# F28x7x_i2c_regs register map
Vendor: Texas Instruments
Peripheral module from a debugger description file (folder C2000).
Address unit: 16 bits
Registers are 16-bit, read-write, no defined reset value unless marked. A register's access mark holds for its fields unless they carry their own. Offsets are as the file gives them; lines under a group give offsets from that group; [hi:lo] are bit positions; {n}, {i} and the like mark numbered series; 'fields as' and 'values as' point back to an identical list; <NAME> marks a mode.

## I2C_REGS
0x00 I2COAR — I2C Own address
  [9:0] OAR
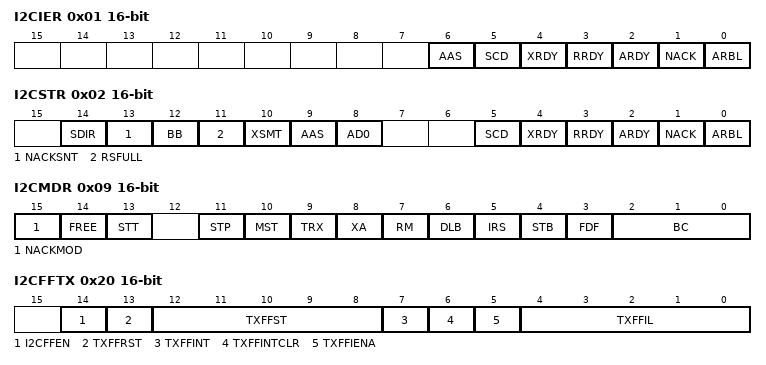
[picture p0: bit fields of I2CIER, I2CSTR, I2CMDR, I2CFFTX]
0x01 I2CIER — I2C Interrupt Enable
  [all] fields
    0=Interrupt request disabled; 1=Interrupt request enabled
  [6] AAS — Addressed as slave interrupt enable
  [5] SCD — Stop condition detected interrupt enable
  [4] XRDY — Transmit-data-ready interrupt enable
  [3] RRDY — Receive-data-ready interrupt enable
  [2] ARDY — Register-access-ready interrupt enable
  [1] NACK — No-acknowledgment interrupt enable
  [0] ARBL — Arbitration-lost interrupt enable
0x02 I2CSTR — I2C Status
  [14] SDIR — Slave direction bit
    0=I2C is not addressed as a slave transmitter; 1=I2C is addressed as a slave transmitter
  [13] NACKSNT — NACK sent bit.
    0=NACK not sent; 1=NACK sent: A no-acknowledge bit was sent during the acknowledge
  [12] BB — Bus busy bit.
    0=Bus free; 1=Bus busy: The I2C module has received or transmitted a START bi
  [11] RSFULL — Receive shift register full bit.
    0=No overrun detected; 1=Overrun detected
  [10] XSMT — Transmit shift register empty bit.
    0=Underflow detected (empty); 1=No underflow detected (not empty)
  [9] AAS — Addressed-as-slave bit
    0=In the 7-bit addressing mode, the AAS bit is cleared when recei; 1=The I2C module has recognized its own slave address or an addre
  [8] AD0 — Address 0 bits
    0=AD0 has been cleared by a START or STOP condition; 1=An address of all zeros (general call) is detected
  [5] SCD — Stop condition detected bit.
    0=STOP condition not detected since SCD was last cleared; 1=A STOP condition has been detected on the I2C bus
  [4] XRDY — Transmit-data-ready interrupt flag bit.
    0=I2CDXR not ready; 1=I2CDXR ready: Data has been copied from I2CDXR to I2CXSR
  [3] RRDY — Receive-data-ready interrupt flag bit.
    0=I2CDRR not ready; 1=I2CDRR ready: Data has been copied from I2CRSR to I2CDRR
  [2] ARDY — Register-access-ready interrupt flag bit
    0=The registers are not ready to be accessed; 1=The registers are ready to be accessed
  [1] NACK — No-acknowledgment interrupt flag bit.
    0=ACK received/NACK not received; 1=NACK bit received
  [0] ARBL — Arbitration-lost interrupt flag bit
    0=Arbitration not lost; 1=Arbitration lost
0x03 I2CCLKL — I2C Clock low-time divider
  [15:0] I2CCLKL — Clock low-time divide-down value.
0x04 I2CCLKH — I2C Clock high-time divider
  [15:0] I2CCLKH — Clock high-time divide-down value.
0x05 I2CCNT — I2C Data count
  [15:0] I2CCNT — Data count value.
0x06 I2CDRR — I2C Data receive
  [7:0] DATA — Receive data
0x07 I2CSAR — I2C Slave address
  [9:0] SAR — Slave Address
0x08 I2CDXR — I2C Data Transmit
  [7:0] DATA — Transmit data
0x09 I2CMDR — I2C Mode
  [15] NACKMOD — NACK mode bit
    0=In the slave-receiver mode: The I2C module sends an acknowledge; 1=In either slave-receiver or master-receiver mode: The I2C modul
  [14] FREE — Debug Action
    0=When I2C module is master:[[br]]If SCL is low when the breakpoi; 1=The I2C module runs free; that is, it continues to operate when
  [13] STT — START condition bit
    0=In the master mode, STT is automatically cleared after the STAR; 1=In the master mode, setting STT to 1 causes the I2C module to g
  [11] STP — STOP Condition
    0=STP is automatically cleared after the STOP condition has been; 1=STP has been set by the device to generate a STOP condition whe
  [10] MST — Master Mode
    0=Slave mode; 1=Master mode
  [9] TRX — Transmitter Mode
    0=Receiver mode; 1=Transmitter mode
  [8] XA — Expanded Address Mode
    0=7-bit addressing mode (normal address mode); 1=10-bit addressing mode (expanded address mode)
  [7] RM — Repeat Mode
    0=Nonrepeat mode; 1=Repeat mode
  [6] DLB — Digital Loopback Mode
    0=Digital loopback mode is disabled; 1=Digital loopback mode is enabled
  [5] IRS — I2C Module Reset
    0=The I2C module is in reset/disabled; 1=The I2C module is enabled
  [4] STB — START Byte Mode
    0=The I2C module is not in the START byte mode; 1=The I2C module is in the START byte mode
  [3] FDF — Free Data Format
    0=Free data format mode is disabled; 1=Free data format mode is enabled
  [2:0] BC — Bit count bits.
    0=8 bits per data byte; 1=1 bit per data byte; {v}=__{v} ({v} bits per data byte) (v=2..7)
0x0A I2CISRC — I2C Interrupt Source
  [2:0] INTCODE — Interrupt code bits.
    0=None; 1=Arbitration lost; 2=__2 (No-acknowledgment condition detected); 3=__3 (Registers ready to be accessed); 4=__4 (Receive data ready); 5=__5 (Transmit data ready); 6=__6 (Stop condition detected); 7=__7 (Addressed as slave)
0x0B I2CEMDR — I2C Extended Mode
  [0] BC — Backwards compatibility mode
    0=See Figure 9-17 for details; 1=See Figure 9-17 for details
0x0C I2CPSC — I2C Prescaler
  [7:0] IPSC — I2C Prescaler Divide Down
0x20 I2CFFTX — I2C FIFO Transmit
  [14] I2CFFEN — Transmit FIFO Enable
    0=Disable the I2C FIFO mode; 1=Enable the I2C FIFO mode
  [13] TXFFRST — Transmit FIFO Reset
    0=Reset the transmit FIFO pointer to 0000 and hold the transmit F; 1=Enable the transmit FIFO operation
  [12:8] TXFFST — Transmit FIFO Status
  [7] TXFFINT — Transmit FIFO Interrupt Flag
    0=Transmit FIFO interrupt condition has not occurred; 1=Transmit FIFO interrupt condition has occurred
  [6] TXFFINTCLR — Transmit FIFO Interrupt Flag Clear
    0=Writes of zeros have no effect. Reads return a 0.; 1=Writing a 1 to this bit clears the TXFFINT flag
  [5] TXFFIENA — Transmit FIFO Interrupt Enable
    0=Disabled. TXFFINT flag does not generate an interrupt when set.; 1=Enabled. TXFFINT flag does generate an interrupt when set.
  [4:0] TXFFIL — Transmit FIFO Interrupt Level
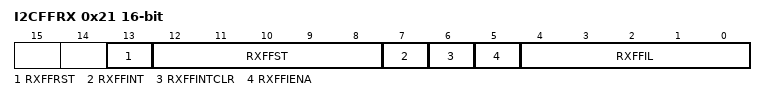
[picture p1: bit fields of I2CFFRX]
0x21 I2CFFRX — I2C FIFO Receive
  [13] RXFFRST — Receive FIFO Reset
    0=Reset the receive FIFO pointer to 0000 and hold the receive FIF; 1=Enable the receive FIFO operation
  [12:8] RXFFST — Receive FIFO Status
  [7] RXFFINT — Receive FIFO Interrupt Flag
    0=Receive FIFO interrupt condition has not occurred; 1=Receive FIFO interrupt condition has occurred
  [6] RXFFINTCLR — Receive FIFO Interrupt Flag Clear
    0=Writes of zeros have no effect. Reads return a zero.; 1=Writing a 1 to this bit clears the RXFFINT flag
  [5] RXFFIENA — Receive FIFO Interrupt Enable
    0=Disabled. RXFFINT flag does not generate an interrupt when set.; 1=Enabled. RXFFINT flag does generate an interrupt when set.
  [4:0] RXFFIL — Receive FIFO Interrupt Level
